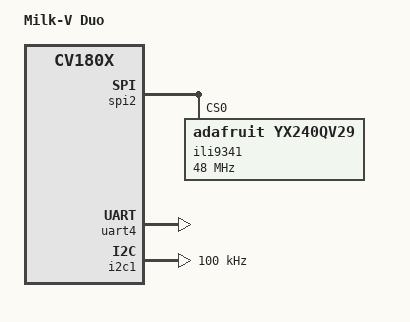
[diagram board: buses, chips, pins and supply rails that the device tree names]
/dts-v1/;
#include "cv180x_base_riscv.dtsi"
#include "cv180x_asic_qfn.dtsi"
#include "cv180x_asic_sd.dtsi"
#include "cv180x_default_memmap.dtsi"

&mipi_rx{
	snsr-reset = <&portc 8 GPIO_ACTIVE_LOW>, <&portc 8 GPIO_ACTIVE_LOW>, <&portc 8 GPIO_ACTIVE_LOW>;
};

&spi2 {
	status = "okay";
	/delete-node/ spidev@0;
	ili9341: ili9341@0{
		compatible = "adafruit,yx240qv29", "ilitek,ili9341";
		reg = <0>;
		status = "okay";
		spi-max-frequency = <48000000>;
		spi-cpol;
		spi-cpha;
		rotation = <0>;
		fps = <60>;
		rgb;
		buswidth = <8>;

		dc = <&porta 24 GPIO_ACTIVE_HIGH>;
		reset = <&porta 23 GPIO_ACTIVE_HIGH>;

		debug = <0x0>;
	};
};

&uart4 {
	status = "okay";
};

&i2c1 {
       status = "okay";
       clock-frequency = <100000>;
};

/ {
	model = "Milk-V Duo";
};

